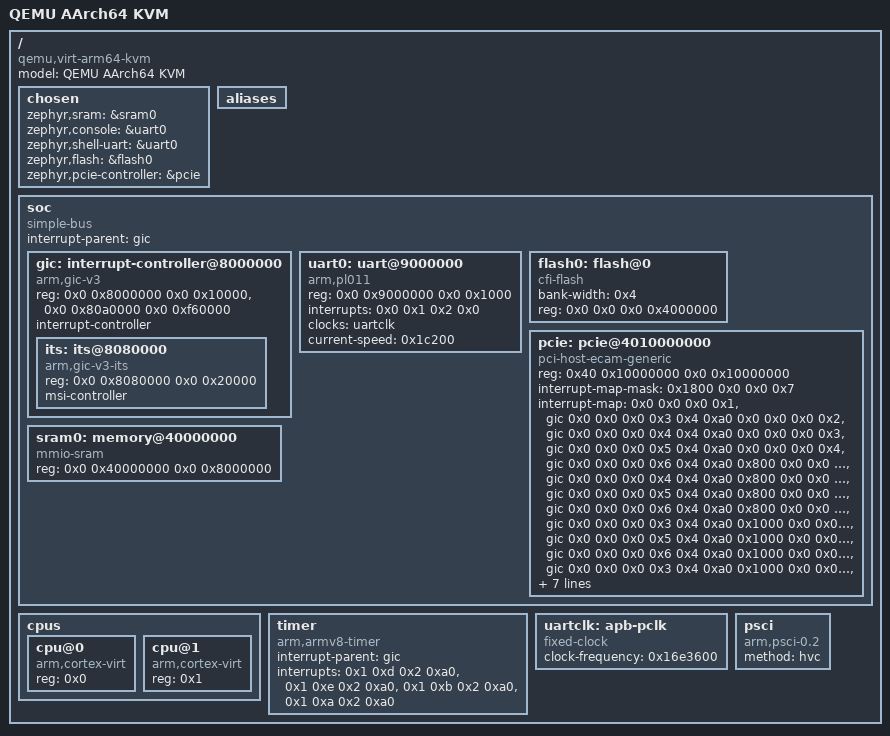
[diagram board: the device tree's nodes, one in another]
/dts-v1/;

/* node '/' defined in zephyr/dts/common/skeleton.dtsi:9 */
/ {
	#address-cells = < 0x2 >;           /* in zephyr/dts/arm64/qemu/qemu-virt-arm64.dtsi:22 */
	#size-cells = < 0x2 >;              /* in zephyr/dts/arm64/qemu/qemu-virt-arm64.dtsi:23 */
	model = "QEMU AArch64 KVM";         /* in zephyr/boards/qemu/kvm_arm64/qemu_kvm_arm64.dts:13 */
	compatible = "qemu,virt-arm64-kvm"; /* in zephyr/boards/qemu/kvm_arm64/qemu_kvm_arm64.dts:14 */

	/* node '/chosen' defined in zephyr/dts/common/skeleton.dtsi:13 */
	chosen {
		zephyr,sram = &sram0;           /* in zephyr/boards/qemu/kvm_arm64/qemu_kvm_arm64.dts:22 */
		zephyr,console = &uart0;        /* in zephyr/boards/qemu/kvm_arm64/qemu_kvm_arm64.dts:23 */
		zephyr,shell-uart = &uart0;     /* in zephyr/boards/qemu/kvm_arm64/qemu_kvm_arm64.dts:24 */
		zephyr,flash = &flash0;         /* in zephyr/boards/qemu/kvm_arm64/qemu_kvm_arm64.dts:25 */
		zephyr,pcie-controller = &pcie; /* in zephyr/boards/qemu/kvm_arm64/qemu_kvm_arm64.dts:26 */
	};

	/* node '/aliases' defined in zephyr/dts/common/skeleton.dtsi:15 */
	aliases {
	};

	/* node '/soc' defined in zephyr/dts/arm64/armv8-a.dtsi:10 */
	soc {
		compatible = "simple-bus";   /* in zephyr/dts/arm64/armv8-a.dtsi:13 */
		#address-cells = < 0x2 >;    /* in zephyr/dts/arm64/qemu/qemu-virt-arm64.dtsi:62 */
		#size-cells = < 0x2 >;       /* in zephyr/dts/arm64/qemu/qemu-virt-arm64.dtsi:63 */
		ranges;                      /* in zephyr/dts/arm64/qemu/qemu-virt-arm64.dtsi:64 */
		interrupt-parent = < &gic >; /* in zephyr/dts/arm64/qemu/qemu-virt-arm64.dtsi:66 */

		/* node '/soc/interrupt-controller@8000000' defined in zephyr/dts/arm64/qemu/qemu-virt-arm64.dtsi:68 */
		gic: interrupt-controller@8000000 {
			compatible = "arm,gic-v3",
			             "arm,gic";               /* in zephyr/dts/arm64/qemu/qemu-virt-arm64.dtsi:69 */
			reg = < 0x0 0x8000000 0x0 0x10000 >,
			      < 0x0 0x80a0000 0x0 0xf60000 >; /* in zephyr/dts/arm64/qemu/qemu-virt-arm64.dtsi:70 */
			interrupt-controller;                 /* in zephyr/dts/arm64/qemu/qemu-virt-arm64.dtsi:72 */
			#interrupt-cells = < 0x4 >;           /* in zephyr/dts/arm64/qemu/qemu-virt-arm64.dtsi:73 */
			status = "okay";                      /* in zephyr/dts/arm64/qemu/qemu-virt-arm64.dtsi:74 */
			#size-cells = < 0x2 >;                /* in zephyr/dts/arm64/qemu/qemu-virt-arm64.dtsi:75 */
			#address-cells = < 0x2 >;             /* in zephyr/dts/arm64/qemu/qemu-virt-arm64.dtsi:76 */
			phandle = < 0x1 >;                    /* in zephyr/dts/arm64/qemu/qemu-virt-arm64.dtsi:66 */

			/* node '/soc/interrupt-controller@8000000/its@8080000' defined in zephyr/dts/arm64/qemu/qemu-virt-arm64.dtsi:78 */
			its: its@8080000 {
				compatible = "arm,gic-v3-its";       /* in zephyr/dts/arm64/qemu/qemu-virt-arm64.dtsi:79 */
				reg = < 0x0 0x8080000 0x0 0x20000 >; /* in zephyr/dts/arm64/qemu/qemu-virt-arm64.dtsi:80 */
				msi-controller;                      /* in zephyr/dts/arm64/qemu/qemu-virt-arm64.dtsi:81 */
				phandle = < 0x3 >;                   /* in zephyr/dts/arm64/qemu/qemu-virt-arm64.dtsi:147 */
			};
		};

		/* node '/soc/uart@9000000' defined in zephyr/dts/arm64/qemu/qemu-virt-arm64.dtsi:85 */
		uart0: uart@9000000 {
			compatible = "arm,pl011";           /* in zephyr/dts/arm64/qemu/qemu-virt-arm64.dtsi:86 */
			reg = < 0x0 0x9000000 0x0 0x1000 >; /* in zephyr/dts/arm64/qemu/qemu-virt-arm64.dtsi:87 */
			interrupts = < 0x0 0x1 0x2 0x0 >;   /* in zephyr/dts/arm64/qemu/qemu-virt-arm64.dtsi:89 */
			interrupt-names = "irq_0";          /* in zephyr/dts/arm64/qemu/qemu-virt-arm64.dtsi:90 */
			clocks = < &uartclk >;              /* in zephyr/dts/arm64/qemu/qemu-virt-arm64.dtsi:91 */
			status = "okay";                    /* in zephyr/boards/qemu/kvm_arm64/qemu_kvm_arm64.dts:38 */
			current-speed = < 0x1c200 >;        /* in zephyr/boards/qemu/kvm_arm64/qemu_kvm_arm64.dts:39 */
		};

		/* node '/soc/flash@0' defined in zephyr/dts/arm64/qemu/qemu-virt-arm64.dtsi:94 */
		flash0: flash@0 {
			compatible = "cfi-flash";        /* in zephyr/dts/arm64/qemu/qemu-virt-arm64.dtsi:95 */
			bank-width = < 0x4 >;            /* in zephyr/dts/arm64/qemu/qemu-virt-arm64.dtsi:96 */
			reg = < 0x0 0x0 0x0 0x4000000 >; /* in zephyr/dts/arm64/qemu/qemu-virt-arm64.dtsi:101 */
		};

		/* node '/soc/pcie@4010000000' defined in zephyr/dts/arm64/qemu/qemu-virt-arm64.dtsi:104 */
		pcie: pcie@4010000000 {
			compatible = "pci-host-ecam-generic";                                                                 /* in zephyr/dts/arm64/qemu/qemu-virt-arm64.dtsi:105 */
			device_type = "pci";                                                                                  /* in zephyr/dts/arm64/qemu/qemu-virt-arm64.dtsi:106 */
			reg = < 0x40 0x10000000 0x0 0x10000000 >;                                                             /* in zephyr/dts/arm64/qemu/qemu-virt-arm64.dtsi:107 */
			#size-cells = < 0x2 >;                                                                                /* in zephyr/dts/arm64/qemu/qemu-virt-arm64.dtsi:108 */
			#address-cells = < 0x3 >;                                                                             /* in zephyr/dts/arm64/qemu/qemu-virt-arm64.dtsi:109 */
			ranges = < 0x1000000 0x0 0x0 0x0 0x3eff0000 0x0 0x10000 0x2000000 0x0 0x10000000 0x0 0x10000000
			           0x0 0x2eff0000 0x3000000 0x80 0x0 0x80 0x0 0x80 0x0 >;                                     /* in zephyr/dts/arm64/qemu/qemu-virt-arm64.dtsi:110 */
			#interrupt-cells = < 0x1 >;                                                                           /* in zephyr/dts/arm64/qemu/qemu-virt-arm64.dtsi:113 */
			interrupt-map-mask = < 0x1800 0x0 0x0 0x7 >;                                                          /* in zephyr/dts/arm64/qemu/qemu-virt-arm64.dtsi:114 */
			interrupt-map = < 0x0 0x0 0x0 0x1 &gic 0x0 0x0 0x0 0x3 0x4 0xa0 0x0 0x0 0x0 0x2 &gic 0x0 0x0 0x0 0x4
			                  0x4 0xa0 0x0 0x0 0x0 0x3 &gic 0x0 0x0 0x0 0x5 0x4 0xa0 0x0 0x0 0x0 0x4 &gic 0x0 0x0
			                  0x0 0x6 0x4 0xa0 0x800 0x0 0x0 0x1 &gic 0x0 0x0 0x0 0x4 0x4 0xa0 0x800 0x0 0x0 0x2
			                  &gic 0x0 0x0 0x0 0x5 0x4 0xa0 0x800 0x0 0x0 0x3 &gic 0x0 0x0 0x0 0x6 0x4 0xa0 0x800
			                  0x0 0x0 0x4 &gic 0x0 0x0 0x0 0x3 0x4 0xa0 0x1000 0x0 0x0 0x1 &gic 0x0 0x0 0x0 0x5
			                  0x4 0xa0 0x1000 0x0 0x0 0x2 &gic 0x0 0x0 0x0 0x6 0x4 0xa0 0x1000 0x0 0x0 0x3 &gic
			                  0x0 0x0 0x0 0x3 0x4 0xa0 0x1000 0x0 0x0 0x4 &gic 0x0 0x0 0x0 0x4 0x4 0xa0 0x1800
			                  0x0 0x0 0x1 &gic 0x0 0x0 0x0 0x6 0x4 0xa0 0x1800 0x0 0x0 0x2 &gic 0x0 0x0 0x0 0x3
			                  0x4 0xa0 0x1800 0x0 0x0 0x3 &gic 0x0 0x0 0x0 0x4 0x4 0xa0 0x1800 0x0 0x0 0x4 &gic
			                  0x0 0x0 0x0 0x5 0x4 0xa0 >;                                                         /* in zephyr/dts/arm64/qemu/qemu-virt-arm64.dtsi:115 */
			msi-parent = < &its >;                                                                                /* in zephyr/dts/arm64/qemu/qemu-virt-arm64.dtsi:147 */
			bus-range = < 0x0 0xff >;                                                                             /* in zephyr/dts/arm64/qemu/qemu-virt-arm64.dtsi:148 */
		};

		/* node '/soc/memory@40000000' defined in zephyr/boards/qemu/kvm_arm64/qemu_kvm_arm64.dts:30 */
		sram0: memory@40000000 {
			compatible = "mmio-sram";               /* in zephyr/boards/qemu/kvm_arm64/qemu_kvm_arm64.dts:31 */
			reg = < 0x0 0x40000000 0x0 0x8000000 >; /* in zephyr/boards/qemu/kvm_arm64/qemu_kvm_arm64.dts:32 */
		};
	};

	/* node '/cpus' defined in zephyr/dts/arm64/qemu/qemu-virt-arm64.dtsi:25 */
	cpus {
		#address-cells = < 0x1 >; /* in zephyr/dts/arm64/qemu/qemu-virt-arm64.dtsi:26 */
		#size-cells = < 0x0 >;    /* in zephyr/dts/arm64/qemu/qemu-virt-arm64.dtsi:27 */

		/* node '/cpus/cpu@0' defined in zephyr/dts/arm64/qemu/qemu-virt-arm64.dtsi:29 */
		cpu@0 {
			device_type = "cpu";            /* in zephyr/dts/arm64/qemu/qemu-virt-arm64.dtsi:30 */
			compatible = "arm,cortex-virt"; /* in zephyr/dts/arm64/qemu/qemu-virt-arm64.dtsi:31 */
			reg = < 0x0 >;                  /* in zephyr/dts/arm64/qemu/qemu-virt-arm64.dtsi:32 */
		};

		/* node '/cpus/cpu@1' defined in zephyr/dts/arm64/qemu/qemu-virt-arm64.dtsi:35 */
		cpu@1 {
			device_type = "cpu";            /* in zephyr/dts/arm64/qemu/qemu-virt-arm64.dtsi:36 */
			compatible = "arm,cortex-virt"; /* in zephyr/dts/arm64/qemu/qemu-virt-arm64.dtsi:37 */
			reg = < 0x1 >;                  /* in zephyr/dts/arm64/qemu/qemu-virt-arm64.dtsi:38 */
		};
	};

	/* node '/timer' defined in zephyr/dts/arm64/qemu/qemu-virt-arm64.dtsi:42 */
	timer {
		compatible = "arm,armv8-timer";    /* in zephyr/dts/arm64/qemu/qemu-virt-arm64.dtsi:43 */
		interrupt-parent = < &gic >;       /* in zephyr/dts/arm64/qemu/qemu-virt-arm64.dtsi:44 */
		interrupts = < 0x1 0xd 0x2 0xa0 >,
		             < 0x1 0xe 0x2 0xa0 >,
		             < 0x1 0xb 0x2 0xa0 >,
		             < 0x1 0xa 0x2 0xa0 >; /* in zephyr/dts/arm64/qemu/qemu-virt-arm64.dtsi:45 */
	};

	/* node '/apb-pclk' defined in zephyr/dts/arm64/qemu/qemu-virt-arm64.dtsi:55 */
	uartclk: apb-pclk {
		compatible = "fixed-clock";      /* in zephyr/dts/arm64/qemu/qemu-virt-arm64.dtsi:56 */
		clock-frequency = < 0x16e3600 >; /* in zephyr/dts/arm64/qemu/qemu-virt-arm64.dtsi:57 */
		#clock-cells = < 0x0 >;          /* in zephyr/dts/arm64/qemu/qemu-virt-arm64.dtsi:58 */
		phandle = < 0x2 >;               /* in zephyr/dts/arm64/qemu/qemu-virt-arm64.dtsi:91 */
	};

	/* node '/psci' defined in zephyr/boards/qemu/kvm_arm64/qemu_kvm_arm64.dts:16 */
	psci {
		compatible = "arm,psci-0.2"; /* in zephyr/boards/qemu/kvm_arm64/qemu_kvm_arm64.dts:17 */
		method = "hvc";              /* in zephyr/boards/qemu/kvm_arm64/qemu_kvm_arm64.dts:18 */
	};
};
